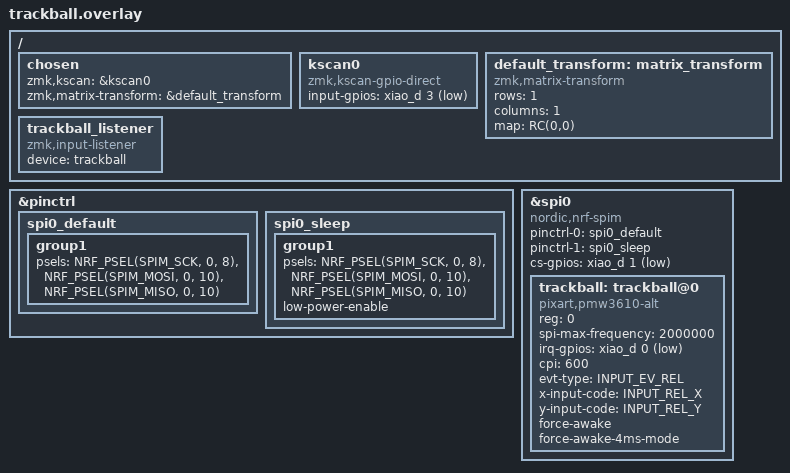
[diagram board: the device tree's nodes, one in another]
#include <dt-bindings/zmk/matrix_transform.h>

&pinctrl {
    spi0_default: spi0_default {
        group1 {
            psels = <NRF_PSEL(SPIM_SCK, 0, 8)>,
                <NRF_PSEL(SPIM_MOSI, 0, 10)>,
                <NRF_PSEL(SPIM_MISO, 0, 10)>;
        };
    };

    spi0_sleep: spi0_sleep {
        group1 {
            psels = <NRF_PSEL(SPIM_SCK, 0, 8)>,
                <NRF_PSEL(SPIM_MOSI, 0, 10)>,
                <NRF_PSEL(SPIM_MISO, 0, 10)>;
            low-power-enable;
        };
    };
};

&spi0 {
    status = "okay";
    compatible = "nordic,nrf-spim";
    pinctrl-0 = <&spi0_default>;
    pinctrl-1 = <&spi0_sleep>;
    pinctrl-names = "default", "sleep";
    cs-gpios = <&xiao_d 1 GPIO_ACTIVE_LOW>;

    trackball: trackball@0 {
		status = "okay";
        compatible = "pixart,pmw3610-alt";
        reg = <0>;
        spi-max-frequency = <2000000>;
        irq-gpios = <&xiao_d 0 (GPIO_ACTIVE_LOW | GPIO_PULL_UP)>;
		cpi = <600>;
        // swap-xy; /* optional */
        // invert-x; /* optional */
        // invert-y; /* optional */
        evt-type = <INPUT_EV_REL>;
        x-input-code = <INPUT_REL_X>;
        y-input-code = <INPUT_REL_Y>;

        force-awake;
        /* keep the sensor awake while ZMK activity state is ACTIVE,
           fallback to normal downshift mode after ZMK goes into IDLE / SLEEP mode.
           thus, the sensor would be a `wakeup-source` */

        force-awake-4ms-mode;
        /* while force-awake is acitvated, enable this mode to force sampling per 
           4ms, where the default sampling rate is 8ms. */
        /* NOTE: apply this mode if you need 250Hz with direct USB connection. */
    };
};



/{
    chosen {
        zmk,kscan = &kscan0;
        zmk,matrix-transform = &default_transform;
    };

    kscan0: kscan0 {
        compatible = "zmk,kscan-gpio-direct";
        input-gpios = <&xiao_d 3 (GPIO_ACTIVE_LOW | GPIO_PULL_UP)>;
        status = "okay";
    };

    default_transform: matrix_transform {
        compatible = "zmk,matrix-transform";
        rows = <1>;
        columns = <1>;
        map = <RC(0,0)>;
    };

	trackball_listener: trackball_listener {
		compatible = "zmk,input-listener";
		device = <&trackball>;
		status = "okay";
	};

};
